# STM32F303x register map
File version: 1.0
Registers are 32-bit, read-write, reset 0x0 unless marked. A register's access mark holds for its fields unless they carry their own. Offsets are from the block's base; [hi:lo] are bit positions; {n}, {i} and the like mark numbered series.

## NVIC — Nested Vectored Interrupt Controller
Base 0xE000E000
0x04 ICTR ro — Interrupt Controller Type Register
  [3:0] INTLINESNUM — Total number of interrupt lines in groups
{0x100+4i} ISER{i} (i=0..2) — Interrupt Set-Enable Register
  [31:0] SETENA
{0x180+4i} ICER{i} (i=0..2) — Interrupt Clear-Enable Register
  [31:0] CLRENA
{0x200+4i} ISPR{i} (i=0..2) — Interrupt Set-Pending Register
  [31:0] SETPEND
{0x280+4i} ICPR{i} (i=0..2) — Interrupt Clear-Pending Register
  [31:0] CLRPEND
{0x300+4i} IABR{i} ro (i=0..2) — Interrupt Active Bit Register
  [31:0] ACTIVE
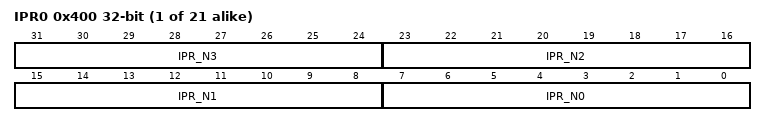
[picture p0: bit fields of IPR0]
{0x400+4i} IPR{i} (i=0..20) — Interrupt Priority Register
  [8n+7:8n] IPR_N{n} (n=0..3)
0xF00 STIR wo — Software Triggered Interrupt Register
  [8:0] INTID — interrupt to be triggered

## FPU — Floting point unit
Base 0xE000ED88
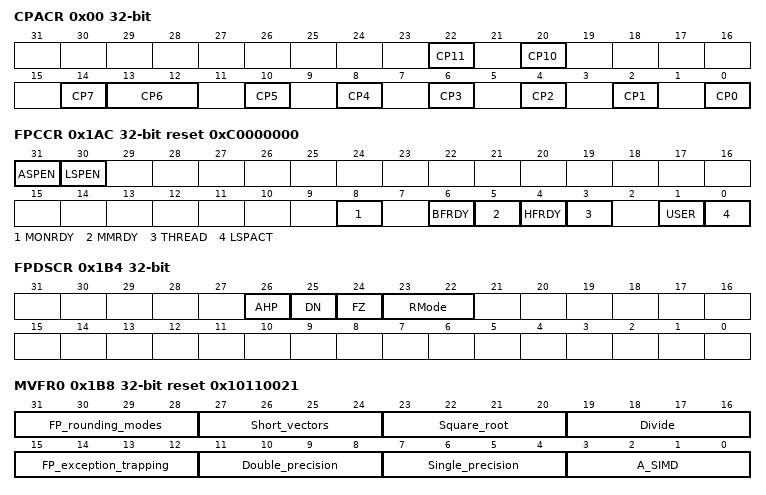
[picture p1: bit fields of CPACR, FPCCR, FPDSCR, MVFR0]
0x00 CPACR — Coprocessor Access Control Register
  [22] CP11 — Access privileges for coprocessor 11
  [20] CP10 — Access privileges for coprocessor 10
  [14] CP7 — Access privileges for coprocessor 7
  [13:12] CP6 — Access privileges for coprocessor 6
  [2n] CP{n} (n=0..5) — Access privileges for coprocessor {n}
0x1AC FPCCR reset 0xC0000000 — FP Context Control Register
  [31] ASPEN, [30] LSPEN, [8] MONRDY, [6] BFRDY, [5] MMRDY, [4] HFRDY, [3] THREAD, [1] USER, [0] LSPACT
0x1B0 FPCAR — FP Context Address Register
  [31:3] ADDRESS
0x1B4 FPDSCR — FP Default Status Control Register
  [26] AHP, [25] DN, [24] FZ, [23:22] RMode
0x1B8 MVFR0 ro reset 0x10110021 — Media and VFP Feature Register 0
  [31:28] FP_rounding_modes
  [27:24] Short_vectors
  [23:20] Square_root
  [19:16] Divide
  [15:12] FP_exception_trapping
  [11:8] Double_precision
  [7:4] Single_precision
  [3:0] A_SIMD — A_SIMD registers
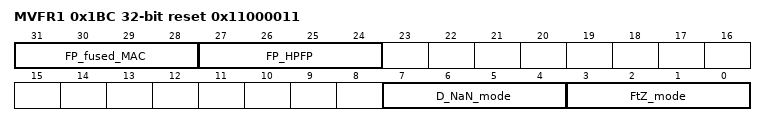
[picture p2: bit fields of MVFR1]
0x1BC MVFR1 ro reset 0x11000011 — Media and VFP Feature Register 1
  [31:28] FP_fused_MAC, [27:24] FP_HPFP, [7:4] D_NaN_mode, [3:0] FtZ_mode

## DBGMCU — Debug support
Base 0xE0042000
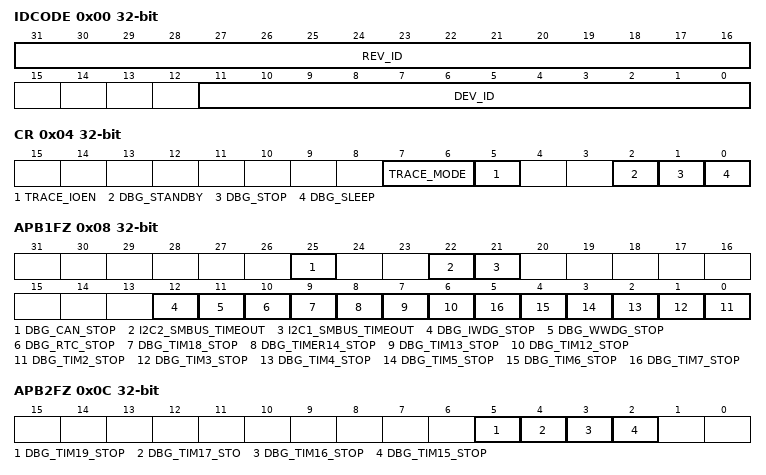
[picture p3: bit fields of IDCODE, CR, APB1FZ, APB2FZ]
0x00 IDCODE ro — MCU Device ID Code Register
  [31:16] REV_ID — Revision Identifier
  [11:0] DEV_ID — Device Identifier
0x04 CR — Debug MCU Configuration Register
  [7:6] TRACE_MODE — Trace pin assignment control
  [5] TRACE_IOEN — Trace pin assignment control
  [2] DBG_STANDBY — Debug Standby Mode
  [1] DBG_STOP — Debug Stop Mode
  [0] DBG_SLEEP — Debug Sleep mode
0x08 APB1FZ — APB Low Freeze Register
  [25] DBG_CAN_STOP — Debug CAN stopped when core is halted
  [22] I2C2_SMBUS_TIMEOUT — SMBUS timeout mode stopped when Core is halted
  [21] I2C1_SMBUS_TIMEOUT — SMBUS timeout mode stopped when Core is halted
  [12] DBG_IWDG_STOP — Debug Independent Wachdog stopped when Core is halted
  [11] DBG_WWDG_STOP — Debug Window Wachdog stopped when Core is halted
  [10] DBG_RTC_STOP — Debug RTC stopped when Core is halted
  [9] DBG_TIM18_STOP — Debug Timer 18 stopped when Core is halted
  [8] DBG_TIMER14_STOP — Debug Timer 14 stopped when Core is halted
  [7] DBG_TIM13_STOP — Debug Timer 13 stopped when Core is halted
  [6] DBG_TIM12_STOP — Debug Timer 12 stopped when Core is halted
  [n-2] DBG_TIM{n}_STOP (n=2..7) — Debug Timer {n} stopped when Core is halted
0x0C APB2FZ — APB High Freeze Register
  [5] DBG_TIM19_STOP — Debug Timer 19 stopped when Core is halted
  [4] DBG_TIM17_STO — Debug Timer 17 stopped when Core is halted
  [3] DBG_TIM16_STOP — Debug Timer 16 stopped when Core is halted
  [2] DBG_TIM15_STOP — Debug Timer 15 stopped when Core is halted

## ADC1_2 — Analog-to-Digital Converter
Base 0x50000000
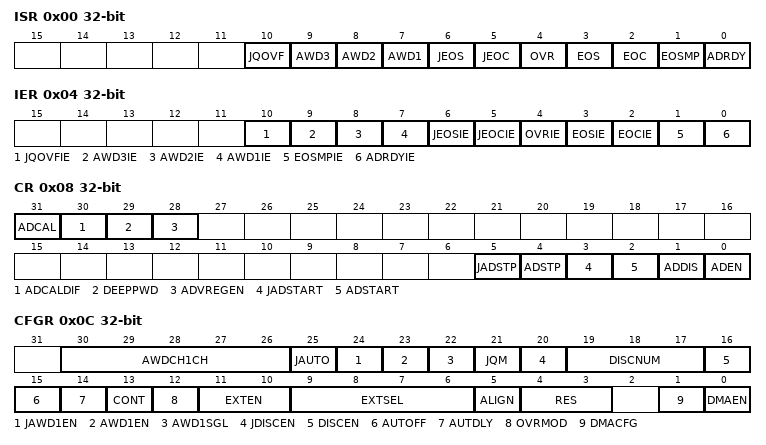
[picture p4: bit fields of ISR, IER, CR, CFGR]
0x00 ISR — interrupt and status register
  [10] JQOVF, [9] AWD3, [8] AWD2, [7] AWD1, [6] JEOS, [5] JEOC, [4] OVR, [3] EOS, [2] EOC, [1] EOSMP, [0] ADRDY
0x04 IER — interrupt enable register
  [10] JQOVFIE, [9] AWD3IE, [8] AWD2IE, [7] AWD1IE, [6] JEOSIE, [5] JEOCIE, [4] OVRIE, [3] EOSIE, [2] EOCIE, [1] EOSMPIE, [0] ADRDYIE
0x08 CR — control register
  [31] ADCAL, [30] ADCALDIF, [29] DEEPPWD, [28] ADVREGEN, [5] JADSTP, [4] ADSTP, [3] JADSTART, [2] ADSTART, [1] ADDIS, [0] ADEN
0x0C CFGR — configuration register
  [30:26] AWDCH1CH, [25] JAUTO, [24] JAWD1EN, [23] AWD1EN, [22] AWD1SGL, [21] JQM, [20] JDISCEN, [19:17] DISCNUM, [16] DISCEN, [15] AUTOFF, [14] AUTDLY, [13] CONT, [12] OVRMOD, [11:10] EXTEN, [9:6] EXTSEL, [5] ALIGN, [4:3] RES, [1] DMACFG, [0] DMAEN
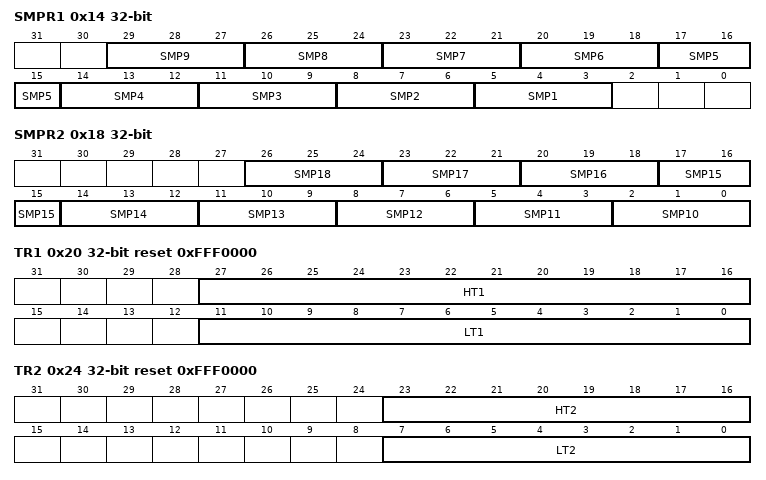
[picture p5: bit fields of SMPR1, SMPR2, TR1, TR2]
0x14 SMPR1 — sample time register 1
  [3n+2:3n] SMP{n} (n=1..9)
0x18 SMPR2 — sample time register 2
  [3n-28:3n-30] SMP{n} (n=10..18)
0x20 TR1 reset 0xFFF0000 — watchdog threshold register 1
  [27:16] HT1, [11:0] LT1
0x24 TR2 reset 0xFFF0000 — watchdog threshold register
  [23:16] HT2, [7:0] LT2
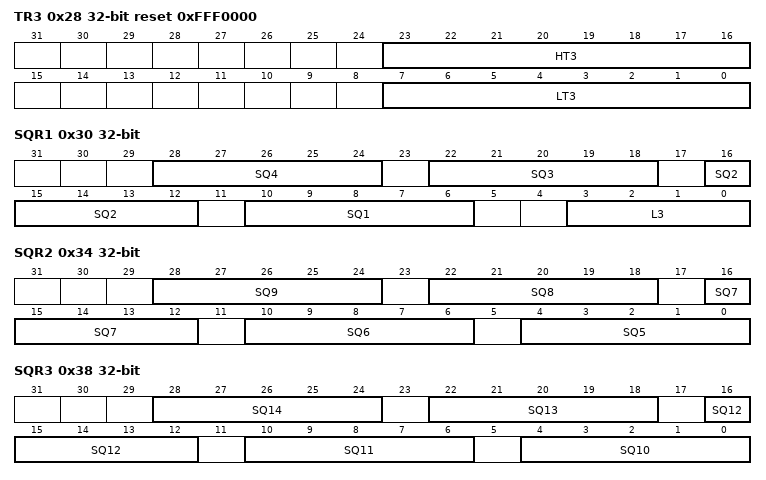
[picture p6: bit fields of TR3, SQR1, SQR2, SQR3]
0x28 TR3 reset 0xFFF0000 — watchdog threshold register 3
  [23:16] HT3, [7:0] LT3
0x30 SQR1 — regular sequence register 1
  [6n+4:6n] SQ{n} (n=1..4), [3:0] L3
0x34 SQR2 — regular sequence register 2
  [6n-26:6n-30] SQ{n} (n=5..9)
0x38 SQR3 — regular sequence register 3
  [6n-56:6n-60] SQ{n} (n=10..14)
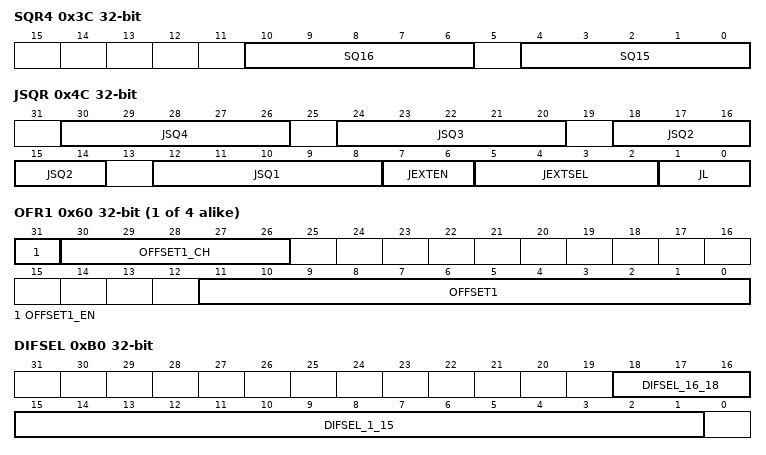
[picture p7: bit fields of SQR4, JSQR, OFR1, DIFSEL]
0x3C SQR4 — regular sequence register 4
  [10:6] SQ16, [4:0] SQ15
0x40 DR ro — regular Data Register
  [15:0] regularDATA
0x4C JSQR — injected sequence register
  [6n+6:6n+2] JSQ{n} (n=1..4), [7:6] JEXTEN, [5:2] JEXTSEL, [1:0] JL
{0x5C+4i} OFR{i} (i=1..4) — offset register {i}
  [31] OFFSET{i}_EN, [30:26] OFFSET{i}_CH, [11:0] OFFSET{i}
{0x7C+4i} JDR{i} ro (i=1..4) — injected data register {i}
  [15:0] JDATA{i}
0xA0 AWD2CR — Analog Watchdog 2 Configuration Register
  [18:1] AWD2CH
0xA4 AWD3CR — Analog Watchdog 3 Configuration Register
  [18:1] AWD3CH
0xB0 DIFSEL access per field — Differential Mode Selection Register 2
  [18:16] DIFSEL_16_18 ro — Differential mode for channels 18 to 16
  [15:1] DIFSEL_1_15 rw — Differential mode for channels 15 to 1
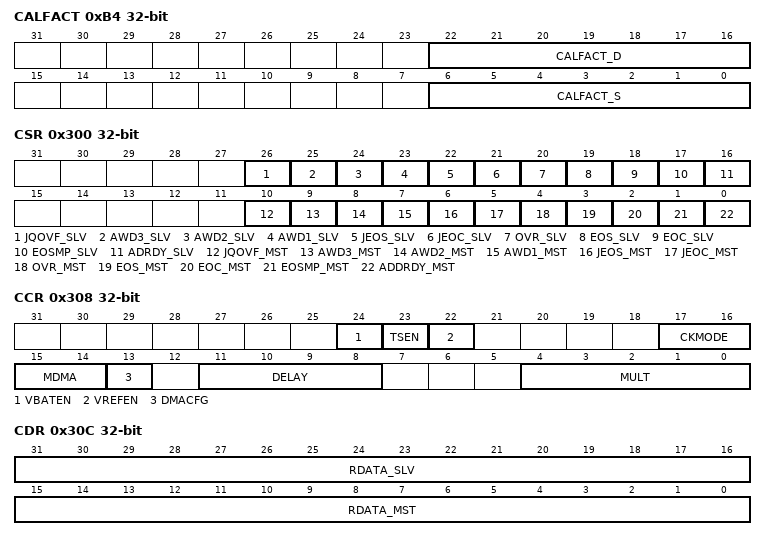
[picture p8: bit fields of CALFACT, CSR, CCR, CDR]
0xB4 CALFACT — Calibration Factors
  [22:16] CALFACT_D, [6:0] CALFACT_S
0x300 CSR ro — ADC Common status register
  [26] JQOVF_SLV — Injected Context Queue Overflow flag of the slave ADC
  [25] AWD3_SLV — Analog watchdog 3 flag of the slave ADC
  [24] AWD2_SLV — Analog watchdog 2 flag of the slave ADC
  [23] AWD1_SLV — Analog watchdog 1 flag of the slave ADC
  [22] JEOS_SLV — End of injected sequence flag of the slave ADC
  [21] JEOC_SLV — End of injected conversion flag of the slave ADC
  [20] OVR_SLV — Overrun flag of the slave ADC
  [19] EOS_SLV — End of regular sequence flag of the slave ADC
  [18] EOC_SLV — End of regular conversion of the slave ADC
  [17] EOSMP_SLV
  [16] ADRDY_SLV
  [10] JQOVF_MST
  [9] AWD3_MST
  [8] AWD2_MST
  [7] AWD1_MST
  [6] JEOS_MST
  [5] JEOC_MST
  [4] OVR_MST
  [3] EOS_MST
  [2] EOC_MST
  [1] EOSMP_MST
  [0] ADDRDY_MST
0x308 CCR — ADC common control register
  [24] VBATEN — VBAT enable
  [23] TSEN — Temperature sensor enable
  [22] VREFEN — VREFINT enable
  [17:16] CKMODE — ADC clock mode
  [15:14] MDMA — Direct memory access mode for multi ADC mode
  [13] DMACFG — DMA configuration (for multi-ADC mode)
  [11:8] DELAY — Delay between 2 sampling phases
  [4:0] MULT — Multi ADC mode selection
0x30C CDR ro — ADC common regular data register for dual and triple modes
  [31:16] RDATA_SLV — Regular data of the slave ADC
  [15:0] RDATA_MST — Regular data of the master ADC
